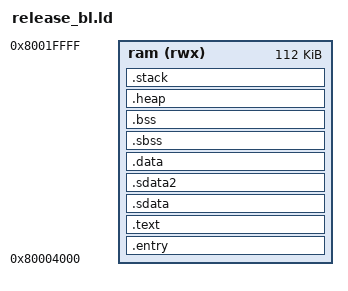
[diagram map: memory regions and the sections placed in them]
OUTPUT_ARCH( "riscv" )
ENTRY(_start)

MEMORY
{
    ram (rwx) : ORIGIN = 0x80004000, LENGTH = 128k - 16k
}

STACK_SIZE          = 2k;               /* needs to be calculated for your application */
HEAP_SIZE           = 0k;               /* needs to be calculated for your application */

SECTIONS
{
  .entry : ALIGN(0x10)
  {
    KEEP (*(SORT_NONE(.entry)))
    . = ALIGN(0x10);
  } > ram

  .text : ALIGN(0x10)
  {
    *(.text .text.* .gnu.linkonce.t.*)
    *(.plt)
    . = ALIGN(0x10);
    
    KEEP (*crtbegin.o(.ctors))
    KEEP (*(EXCLUDE_FILE (*crtend.o) .ctors))
    KEEP (*(SORT(.ctors.*)))
    KEEP (*crtend.o(.ctors))
    KEEP (*crtbegin.o(.dtors))
    KEEP (*(EXCLUDE_FILE (*crtend.o) .dtors))
    KEEP (*(SORT(.dtors.*)))
    KEEP (*crtend.o(.dtors)) 
    
    *(.rodata .rodata.* .gnu.linkonce.r.*)
    *(.gcc_except_table) 
    *(.eh_frame_hdr)
    *(.eh_frame)
    
    KEEP (*(.init))
    KEEP (*(.fini))

    PROVIDE_HIDDEN (__preinit_array_start = .);
    KEEP (*(.preinit_array))
    PROVIDE_HIDDEN (__preinit_array_end = .);
    PROVIDE_HIDDEN (__init_array_start = .);
    KEEP (*(SORT(.init_array.*)))
    KEEP (*(.init_array))
    PROVIDE_HIDDEN (__init_array_end = .);
    PROVIDE_HIDDEN (__fini_array_start = .);
    KEEP (*(.fini_array))
    KEEP (*(SORT(.fini_array.*)))
    PROVIDE_HIDDEN (__fini_array_end = .);
    . = ALIGN(0x10);
    
  } > ram

  /* short/global data section */
  .sdata : ALIGN(0x10)
  {
    __sdata_load = LOADADDR(.sdata);
    __sdata_start = .; 
    PROVIDE( __global_pointer$ = . + 0x800);
    *(.srodata.cst16) *(.srodata.cst8) *(.srodata.cst4) *(.srodata.cst2)
    *(.srodata*)
    *(.sdata .sdata.* .gnu.linkonce.s.*)
    KEEP (*(.sdata))
    . = ALIGN(0x10);
    __sdata_end = .;
  } > ram
  
.sdata2 : 
{
    . = ALIGN(0x10);
    PROVIDE( __sdata2_start = . );
    *(.sdata2 .sdata2.*)
    *(.gnu.linkonce.s2.*)
    KEEP (*(.sdata2))
    . = ALIGN(4);
    PROVIDE( __sdata2_end = . );
} > ram

  /* data section */
  .data : ALIGN(0x10)
  { 
    __data_load = LOADADDR(.data);
    __data_start = .; 
    *(.got.plt) *(.got)
    *(.shdata)
    *(.data .data.* .gnu.linkonce.d.*)
    . = ALIGN(0x10);
    __data_end = .;
    /*_edata = .;   */
  } > ram

  /* sbss section */
  .sbss : ALIGN(0x10)
  {
    __sbss_start = .;
    *(.sbss .sbss.* .gnu.linkonce.sb.*)
    *(.scommon)
    . = ALIGN(0x10);
    __sbss_end = .;
  } > ram
  
  /* sbss section */
  .bss : ALIGN(0x10)
  { 
    __bss_start = .;
    *(.shbss)
    *(.bss .bss.* .gnu.linkonce.b.*)
    *(COMMON)
    . = ALIGN(0x10);
    __bss_end = .;
  } > ram

  /* End of uninitialized data segment */
  _end = .;
  
  .heap : ALIGN(0x10)
  {
    __heap_start = .;
    . += HEAP_SIZE;
    __heap_end = .;
    . = ALIGN(0x10);
    _heap_end = __heap_end;
  } > ram
  
  .stack : ALIGN(0x10)
  {
    __stack_bottom = .;
    . += STACK_SIZE;
    __stack_top = .;
    __freertos_irq_stack_top = .;
  } > ram
}

